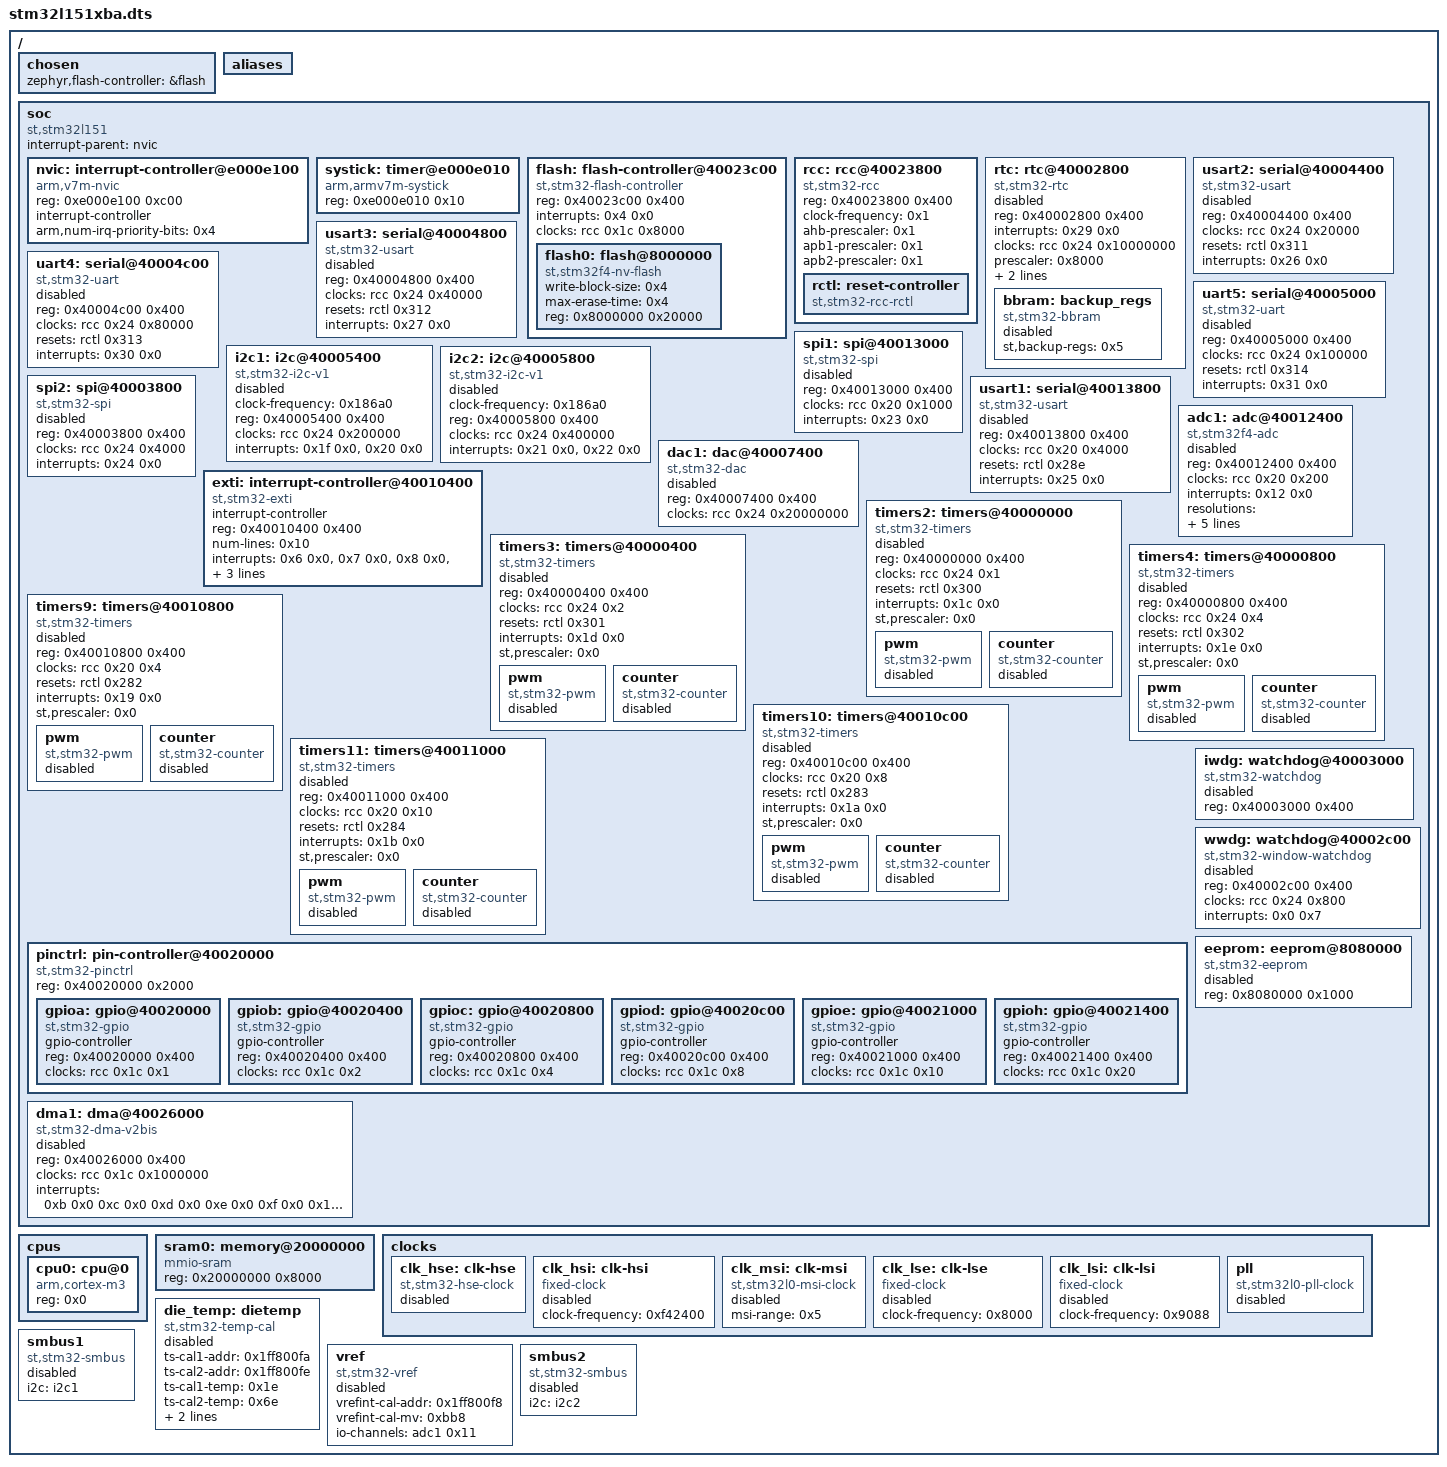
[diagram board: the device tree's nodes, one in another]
/dts-v1/;

/ {
	#address-cells = < 0x1 >;
	#size-cells = < 0x1 >;
	chosen {
		zephyr,flash-controller = &flash;
	};
	aliases {
	};
	soc {
		#address-cells = < 0x1 >;
		#size-cells = < 0x1 >;
		compatible = "st,stm32l151", "st,stm32l1", "simple-bus";
		interrupt-parent = < &nvic >;
		ranges;
		nvic: interrupt-controller@e000e100 {
			#address-cells = < 0x1 >;
			compatible = "arm,v7m-nvic";
			reg = < 0xe000e100 0xc00 >;
			interrupt-controller;
			#interrupt-cells = < 0x2 >;
			arm,num-irq-priority-bits = < 0x4 >;
			phandle = < 0x1 >;
		};
		systick: timer@e000e010 {
			compatible = "arm,armv7m-systick";
			reg = < 0xe000e010 0x10 >;
		};
		flash: flash-controller@40023c00 {
			compatible = "st,stm32-flash-controller", "st,stm32f1-flash-controller";
			reg = < 0x40023c00 0x400 >;
			interrupts = < 0x4 0x0 >;
			clocks = < &rcc 0x1c 0x8000 >;
			#address-cells = < 0x1 >;
			#size-cells = < 0x1 >;
			flash0: flash@8000000 {
				compatible = "st,stm32f4-nv-flash", "st,stm32-nv-flash", "soc-nv-flash";
				write-block-size = < 0x4 >;
				max-erase-time = < 0x4 >;
				reg = < 0x8000000 0x20000 >;
			};
		};
		rcc: rcc@40023800 {
			compatible = "st,stm32-rcc";
			#clock-cells = < 0x2 >;
			reg = < 0x40023800 0x400 >;
			clock-frequency = < 0x1 >;
			ahb-prescaler = < 0x1 >;
			apb1-prescaler = < 0x1 >;
			apb2-prescaler = < 0x1 >;
			phandle = < 0x2 >;
			rctl: reset-controller {
				compatible = "st,stm32-rcc-rctl";
				#reset-cells = < 0x1 >;
				phandle = < 0x3 >;
			};
		};
		rtc: rtc@40002800 {
			compatible = "st,stm32-rtc";
			reg = < 0x40002800 0x400 >;
			interrupts = < 0x29 0x0 >;
			clocks = < &rcc 0x24 0x10000000 >;
			prescaler = < 0x8000 >;
			alarms-count = < 0x2 >;
			alrm-exti-line = < 0x11 >;
			status = "disabled";
			bbram: backup_regs {
				compatible = "st,stm32-bbram";
				st,backup-regs = < 0x5 >;
				status = "disabled";
			};
		};
		usart2: serial@40004400 {
			compatible = "st,stm32-usart", "st,stm32-uart";
			reg = < 0x40004400 0x400 >;
			clocks = < &rcc 0x24 0x20000 >;
			resets = < &rctl 0x311 >;
			interrupts = < 0x26 0x0 >;
			status = "disabled";
		};
		usart3: serial@40004800 {
			compatible = "st,stm32-usart", "st,stm32-uart";
			reg = < 0x40004800 0x400 >;
			clocks = < &rcc 0x24 0x40000 >;
			resets = < &rctl 0x312 >;
			interrupts = < 0x27 0x0 >;
			status = "disabled";
		};
		uart4: serial@40004c00 {
			compatible = "st,stm32-uart";
			reg = < 0x40004c00 0x400 >;
			clocks = < &rcc 0x24 0x80000 >;
			resets = < &rctl 0x313 >;
			interrupts = < 0x30 0x0 >;
			status = "disabled";
		};
		uart5: serial@40005000 {
			compatible = "st,stm32-uart";
			reg = < 0x40005000 0x400 >;
			clocks = < &rcc 0x24 0x100000 >;
			resets = < &rctl 0x314 >;
			interrupts = < 0x31 0x0 >;
			status = "disabled";
		};
		i2c1: i2c@40005400 {
			compatible = "st,stm32-i2c-v1";
			clock-frequency = < 0x186a0 >;
			#address-cells = < 0x1 >;
			#size-cells = < 0x0 >;
			reg = < 0x40005400 0x400 >;
			clocks = < &rcc 0x24 0x200000 >;
			interrupts = < 0x1f 0x0 >, < 0x20 0x0 >;
			interrupt-names = "event", "error";
			status = "disabled";
			phandle = < 0x5 >;
		};
		i2c2: i2c@40005800 {
			compatible = "st,stm32-i2c-v1";
			clock-frequency = < 0x186a0 >;
			#address-cells = < 0x1 >;
			#size-cells = < 0x0 >;
			reg = < 0x40005800 0x400 >;
			clocks = < &rcc 0x24 0x400000 >;
			interrupts = < 0x21 0x0 >, < 0x22 0x0 >;
			interrupt-names = "event", "error";
			status = "disabled";
			phandle = < 0x6 >;
		};
		spi1: spi@40013000 {
			compatible = "st,stm32-spi";
			#address-cells = < 0x1 >;
			#size-cells = < 0x0 >;
			reg = < 0x40013000 0x400 >;
			clocks = < &rcc 0x20 0x1000 >;
			interrupts = < 0x23 0x0 >;
			status = "disabled";
		};
		spi2: spi@40003800 {
			compatible = "st,stm32-spi";
			#address-cells = < 0x1 >;
			#size-cells = < 0x0 >;
			reg = < 0x40003800 0x400 >;
			clocks = < &rcc 0x24 0x4000 >;
			interrupts = < 0x24 0x0 >;
			status = "disabled";
		};
		usart1: serial@40013800 {
			compatible = "st,stm32-usart", "st,stm32-uart";
			reg = < 0x40013800 0x400 >;
			clocks = < &rcc 0x20 0x4000 >;
			resets = < &rctl 0x28e >;
			interrupts = < 0x25 0x0 >;
			status = "disabled";
		};
		adc1: adc@40012400 {
			compatible = "st,stm32f4-adc", "st,stm32-adc";
			reg = < 0x40012400 0x400 >;
			clocks = < &rcc 0x20 0x200 >;
			interrupts = < 0x12 0x0 >;
			status = "disabled";
			#io-channel-cells = < 0x1 >;
			resolutions = < 0x607804 0x517804 0x427804 0x337804 >;
			sampling-times = < 0x4 0x9 0x10 0x18 0x30 0x60 0xc0 0x180 >;
			st,adc-clock-source = < 0x2 >;
			st,adc-sequencer = < 0x1 >;
			phandle = < 0x4 >;
		};
		dac1: dac@40007400 {
			compatible = "st,stm32-dac";
			reg = < 0x40007400 0x400 >;
			clocks = < &rcc 0x24 0x20000000 >;
			status = "disabled";
			#io-channel-cells = < 0x1 >;
		};
		exti: interrupt-controller@40010400 {
			compatible = "st,stm32-exti";
			interrupt-controller;
			#interrupt-cells = < 0x1 >;
			#address-cells = < 0x1 >;
			reg = < 0x40010400 0x400 >;
			num-lines = < 0x10 >;
			interrupts = < 0x6 0x0 >, < 0x7 0x0 >, < 0x8 0x0 >, < 0x9 0x0 >, < 0xa 0x0 >, < 0x17 0x0 >, < 0x28 0x0 >;
			interrupt-names = "line0", "line1", "line2", "line3", "line4", "line5-9", "line10-15";
			line-ranges = < 0x0 0x1 >, < 0x1 0x1 >, < 0x2 0x1 >, < 0x3 0x1 >, < 0x4 0x1 >, < 0x5 0x5 >, < 0xa 0x6 >;
		};
		timers2: timers@40000000 {
			compatible = "st,stm32-timers";
			reg = < 0x40000000 0x400 >;
			clocks = < &rcc 0x24 0x1 >;
			resets = < &rctl 0x300 >;
			interrupts = < 0x1c 0x0 >;
			interrupt-names = "global";
			st,prescaler = < 0x0 >;
			status = "disabled";
			pwm {
				compatible = "st,stm32-pwm";
				status = "disabled";
				#pwm-cells = < 0x3 >;
			};
			counter {
				compatible = "st,stm32-counter";
				status = "disabled";
			};
		};
		timers3: timers@40000400 {
			compatible = "st,stm32-timers";
			reg = < 0x40000400 0x400 >;
			clocks = < &rcc 0x24 0x2 >;
			resets = < &rctl 0x301 >;
			interrupts = < 0x1d 0x0 >;
			interrupt-names = "global";
			st,prescaler = < 0x0 >;
			status = "disabled";
			pwm {
				compatible = "st,stm32-pwm";
				status = "disabled";
				#pwm-cells = < 0x3 >;
			};
			counter {
				compatible = "st,stm32-counter";
				status = "disabled";
			};
		};
		timers4: timers@40000800 {
			compatible = "st,stm32-timers";
			reg = < 0x40000800 0x400 >;
			clocks = < &rcc 0x24 0x4 >;
			resets = < &rctl 0x302 >;
			interrupts = < 0x1e 0x0 >;
			interrupt-names = "global";
			st,prescaler = < 0x0 >;
			status = "disabled";
			pwm {
				compatible = "st,stm32-pwm";
				status = "disabled";
				#pwm-cells = < 0x3 >;
			};
			counter {
				compatible = "st,stm32-counter";
				status = "disabled";
			};
		};
		timers9: timers@40010800 {
			compatible = "st,stm32-timers";
			reg = < 0x40010800 0x400 >;
			clocks = < &rcc 0x20 0x4 >;
			resets = < &rctl 0x282 >;
			interrupts = < 0x19 0x0 >;
			interrupt-names = "global";
			st,prescaler = < 0x0 >;
			status = "disabled";
			pwm {
				compatible = "st,stm32-pwm";
				status = "disabled";
				#pwm-cells = < 0x3 >;
			};
			counter {
				compatible = "st,stm32-counter";
				status = "disabled";
			};
		};
		timers10: timers@40010c00 {
			compatible = "st,stm32-timers";
			reg = < 0x40010c00 0x400 >;
			clocks = < &rcc 0x20 0x8 >;
			resets = < &rctl 0x283 >;
			interrupts = < 0x1a 0x0 >;
			interrupt-names = "global";
			st,prescaler = < 0x0 >;
			status = "disabled";
			pwm {
				compatible = "st,stm32-pwm";
				status = "disabled";
				#pwm-cells = < 0x3 >;
			};
			counter {
				compatible = "st,stm32-counter";
				status = "disabled";
			};
		};
		timers11: timers@40011000 {
			compatible = "st,stm32-timers";
			reg = < 0x40011000 0x400 >;
			clocks = < &rcc 0x20 0x10 >;
			resets = < &rctl 0x284 >;
			interrupts = < 0x1b 0x0 >;
			interrupt-names = "global";
			st,prescaler = < 0x0 >;
			status = "disabled";
			pwm {
				compatible = "st,stm32-pwm";
				status = "disabled";
				#pwm-cells = < 0x3 >;
			};
			counter {
				compatible = "st,stm32-counter";
				status = "disabled";
			};
		};
		pinctrl: pin-controller@40020000 {
			compatible = "st,stm32-pinctrl";
			#address-cells = < 0x1 >;
			#size-cells = < 0x1 >;
			reg = < 0x40020000 0x2000 >;
			gpioa: gpio@40020000 {
				compatible = "st,stm32-gpio";
				gpio-controller;
				#gpio-cells = < 0x2 >;
				reg = < 0x40020000 0x400 >;
				clocks = < &rcc 0x1c 0x1 >;
			};
			gpiob: gpio@40020400 {
				compatible = "st,stm32-gpio";
				gpio-controller;
				#gpio-cells = < 0x2 >;
				reg = < 0x40020400 0x400 >;
				clocks = < &rcc 0x1c 0x2 >;
			};
			gpioc: gpio@40020800 {
				compatible = "st,stm32-gpio";
				gpio-controller;
				#gpio-cells = < 0x2 >;
				reg = < 0x40020800 0x400 >;
				clocks = < &rcc 0x1c 0x4 >;
			};
			gpiod: gpio@40020c00 {
				compatible = "st,stm32-gpio";
				gpio-controller;
				#gpio-cells = < 0x2 >;
				reg = < 0x40020c00 0x400 >;
				clocks = < &rcc 0x1c 0x8 >;
			};
			gpioe: gpio@40021000 {
				compatible = "st,stm32-gpio";
				gpio-controller;
				#gpio-cells = < 0x2 >;
				reg = < 0x40021000 0x400 >;
				clocks = < &rcc 0x1c 0x10 >;
			};
			gpioh: gpio@40021400 {
				compatible = "st,stm32-gpio";
				gpio-controller;
				#gpio-cells = < 0x2 >;
				reg = < 0x40021400 0x400 >;
				clocks = < &rcc 0x1c 0x20 >;
			};
		};
		iwdg: watchdog@40003000 {
			compatible = "st,stm32-watchdog";
			reg = < 0x40003000 0x400 >;
			status = "disabled";
		};
		wwdg: watchdog@40002c00 {
			compatible = "st,stm32-window-watchdog";
			reg = < 0x40002c00 0x400 >;
			clocks = < &rcc 0x24 0x800 >;
			interrupts = < 0x0 0x7 >;
			status = "disabled";
		};
		eeprom: eeprom@8080000 {
			compatible = "st,stm32-eeprom";
			status = "disabled";
			reg = < 0x8080000 0x1000 >;
		};
		dma1: dma@40026000 {
			compatible = "st,stm32-dma-v2bis";
			#dma-cells = < 0x2 >;
			reg = < 0x40026000 0x400 >;
			clocks = < &rcc 0x1c 0x1000000 >;
			interrupts = < 0xb 0x0 0xc 0x0 0xd 0x0 0xe 0x0 0xf 0x0 0x10 0x0 0x11 0x0 >;
			status = "disabled";
		};
	};
	cpus {
		#address-cells = < 0x1 >;
		#size-cells = < 0x0 >;
		cpu0: cpu@0 {
			device_type = "cpu";
			compatible = "arm,cortex-m3";
			reg = < 0x0 >;
		};
	};
	sram0: memory@20000000 {
		compatible = "mmio-sram";
		reg = < 0x20000000 0x8000 >;
	};
	clocks {
		clk_hse: clk-hse {
			#clock-cells = < 0x0 >;
			compatible = "st,stm32-hse-clock";
			status = "disabled";
		};
		clk_hsi: clk-hsi {
			#clock-cells = < 0x0 >;
			compatible = "fixed-clock";
			clock-frequency = < 0xf42400 >;
			status = "disabled";
		};
		clk_msi: clk-msi {
			#clock-cells = < 0x0 >;
			compatible = "st,stm32l0-msi-clock";
			msi-range = < 0x5 >;
			status = "disabled";
		};
		clk_lse: clk-lse {
			#clock-cells = < 0x0 >;
			compatible = "fixed-clock";
			clock-frequency = < 0x8000 >;
			status = "disabled";
		};
		clk_lsi: clk-lsi {
			#clock-cells = < 0x0 >;
			compatible = "fixed-clock";
			clock-frequency = < 0x9088 >;
			status = "disabled";
		};
		pll: pll {
			#clock-cells = < 0x0 >;
			compatible = "st,stm32l0-pll-clock";
			status = "disabled";
		};
	};
	die_temp: dietemp {
		compatible = "st,stm32-temp-cal";
		ts-cal1-addr = < 0x1ff800fa >;
		ts-cal2-addr = < 0x1ff800fe >;
		ts-cal1-temp = < 0x1e >;
		ts-cal2-temp = < 0x6e >;
		ts-cal-vrefanalog = < 0xbb8 >;
		io-channels = < &adc1 0x10 >;
		status = "disabled";
	};
	vref: vref {
		compatible = "st,stm32-vref";
		vrefint-cal-addr = < 0x1ff800f8 >;
		vrefint-cal-mv = < 0xbb8 >;
		io-channels = < &adc1 0x11 >;
		status = "disabled";
	};
	smbus1: smbus1 {
		compatible = "st,stm32-smbus";
		#address-cells = < 0x1 >;
		#size-cells = < 0x0 >;
		i2c = < &i2c1 >;
		status = "disabled";
	};
	smbus2: smbus2 {
		compatible = "st,stm32-smbus";
		#address-cells = < 0x1 >;
		#size-cells = < 0x0 >;
		i2c = < &i2c2 >;
		status = "disabled";
	};
};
